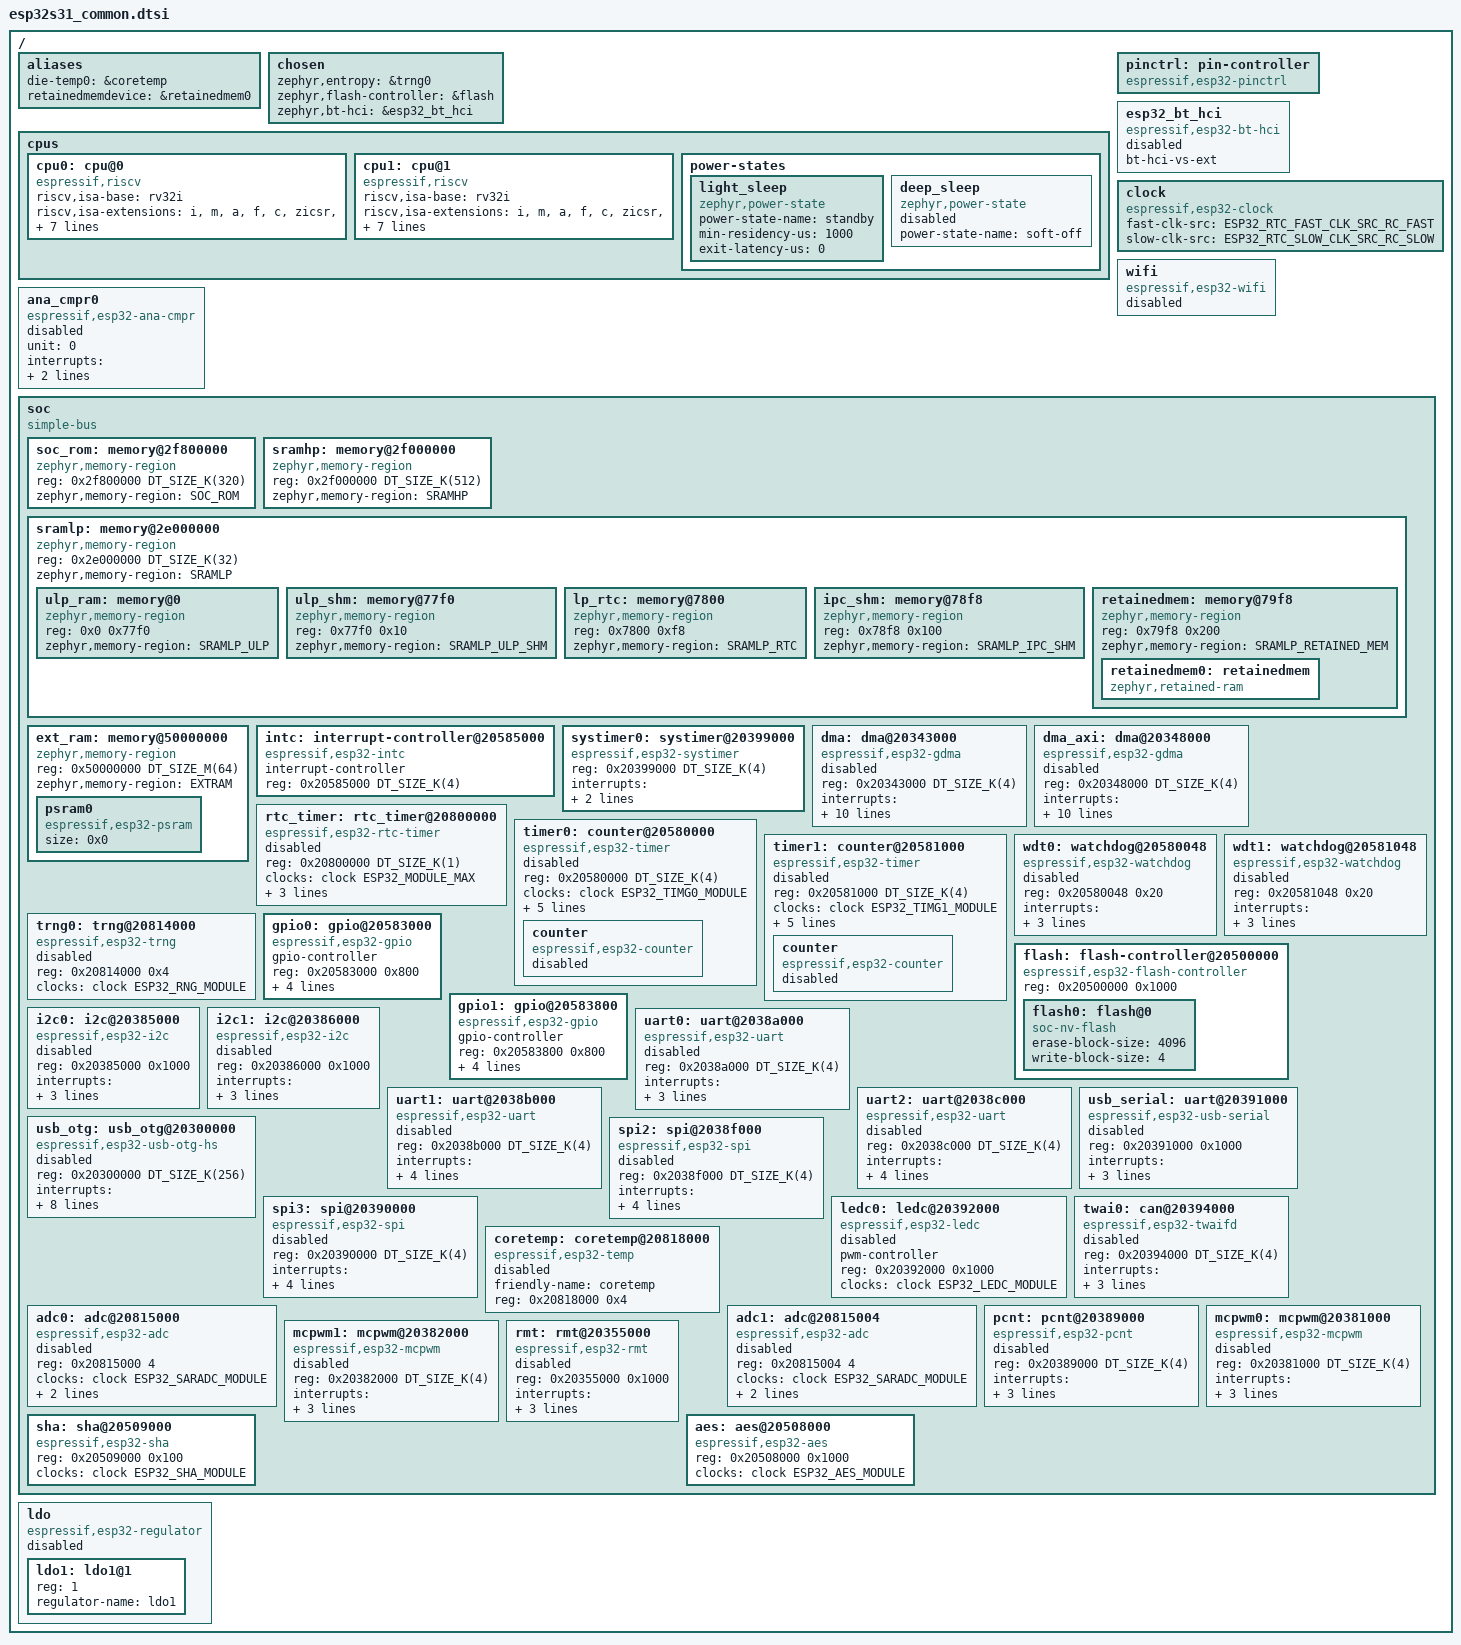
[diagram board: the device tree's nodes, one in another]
/*
 * Copyright (c) 2026 Espressif Systems (Shanghai) Co., Ltd.
 *
 * SPDX-License-Identifier: Apache-2.0
 */
#include <mem.h>
#include <freq.h>
#include <zephyr/dt-bindings/adc/adc.h>
#include <zephyr/dt-bindings/gpio/gpio.h>
#include <zephyr/dt-bindings/i2c/i2c.h>
#include <zephyr/dt-bindings/interrupt-controller/esp-esp32s31-intmux.h>
#include <zephyr/dt-bindings/clock/esp32s31_clock.h>
#include <zephyr/dt-bindings/pinctrl/esp32s31-pinctrl.h>
#include <zephyr/dt-bindings/memory-attr/memory-attr-riscv.h>

/ {
	#address-cells = <1>;
	#size-cells = <1>;

	aliases {
		die-temp0 = &coretemp;
		retainedmemdevice = &retainedmem0;
	};

	chosen {
		zephyr,entropy = &trng0;
		zephyr,flash-controller = &flash;
		zephyr,bt-hci = &esp32_bt_hci;
	};

	cpus {
		#address-cells = <1>;
		#size-cells = <0>;

		cpu0: cpu@0 {
			device_type = "cpu";
			compatible = "espressif,riscv", "riscv";
			riscv,isa-base = "rv32i";
			riscv,isa-extensions = "i", "m", "a", "f", "c", "zicsr", "zifencei";
			reg = <0>;
			cpu-power-states = <&light_sleep &deep_sleep>;
			clock-source = <ESP32_CPU_CLK_SRC_PLL>;
			clock-frequency = <DT_FREQ_M(320)>;
			xtal-freq = <DT_FREQ_M(40)>;
			d-cache-line-size = <32>;
		};

		cpu1: cpu@1 {
			device_type = "cpu";
			compatible = "espressif,riscv", "riscv";
			riscv,isa-base = "rv32i";
			riscv,isa-extensions = "i", "m", "a", "f", "c", "zicsr", "zifencei";
			reg = <1>;
			cpu-power-states = <&light_sleep &deep_sleep>;
			clock-source = <ESP32_CPU_CLK_SRC_PLL>;
			clock-frequency = <DT_FREQ_M(320)>;
			xtal-freq = <DT_FREQ_M(40)>;
			d-cache-line-size = <32>;
		};

		power-states {
			light_sleep: light_sleep {
				compatible = "zephyr,power-state";
				power-state-name = "standby";
				min-residency-us = <1000>;
				exit-latency-us = <0>;
			};

			deep_sleep: deep_sleep {
				/* Deep sleep must be entered using pm_state_force()
				 * or sys_poweroff() calls only
				 */
				compatible = "zephyr,power-state";
				power-state-name = "soft-off";
				status = "disabled";
			};
		};
	};

	pinctrl: pin-controller {
		compatible = "espressif,esp32-pinctrl";
		status = "okay";
	};

	esp32_bt_hci: esp32_bt_hci {
		compatible = "espressif,esp32-bt-hci";
		bt-hci-vs-ext;
		status = "disabled";
	};

	clock: clock {
		compatible = "espressif,esp32-clock";
		fast-clk-src = <ESP32_RTC_FAST_CLK_SRC_RC_FAST>;
		slow-clk-src = <ESP32_RTC_SLOW_CLK_SRC_RC_SLOW>;
		#clock-cells = <1>;
		status = "okay";
	};

	wifi: wifi {
		compatible = "espressif,esp32-wifi";
		status = "disabled";
	};

	ana_cmpr0: ana_cmpr0 {
		compatible = "espressif,esp32-ana-cmpr";
		unit = <0>;
		interrupts = <ZERO_DET_INTR_SOURCE IRQ_DEFAULT_PRIORITY 0>;
		interrupt-parent = <&intc>;
		status = "disabled";
	};

	soc {
		#address-cells = <1>;
		#size-cells = <1>;
		compatible = "simple-bus";
		ranges;

		/*
		 * ESP32-S31 masked ROM (0x2F800000-0x2F850000, 320 KB),
		 * containing libc and other utility functions the app calls
		 * into. PMP protection for this region is configured via
		 * PMP_SOC_REGION_DEFINE in pmp_regions.c.
		 */
		soc_rom: memory@2f800000 {
			compatible = "zephyr,memory-region";
			reg = <0x2f800000 DT_SIZE_K(320)>;
			zephyr,memory-region = "SOC_ROM";
		};

		sramhp: memory@2f000000 {
			compatible = "zephyr,memory-region", "mmio-sram";
			reg = <0x2f000000 DT_SIZE_K(512)>;
			zephyr,memory-region = "SRAMHP";
		};

		sramlp: memory@2e000000 {
			#address-cells = <1>;
			#size-cells = <1>;
			compatible = "zephyr,memory-region", "mmio-sram";
			reg = <0x2e000000 DT_SIZE_K(32)>;
			zephyr,memory-region = "SRAMLP";
			ranges = <0x0 0x2e000000 DT_SIZE_K(32)>;

			ulp_ram: memory@0 {
				compatible = "zephyr,memory-region", "mmio-sram";
				reg = <0x0 0x77f0>;
				zephyr,memory-region = "SRAMLP_ULP";
			};

			ulp_shm: memory@77f0 {
				compatible = "zephyr,memory-region", "mmio-sram";
				reg = <0x77f0 0x10>;
				zephyr,memory-region = "SRAMLP_ULP_SHM";
			};

			lp_rtc: memory@7800 {
				compatible = "zephyr,memory-region", "mmio-sram";
				reg = <0x7800 0xf8>;
				zephyr,memory-region = "SRAMLP_RTC";
			};

			ipc_shm: memory@78f8 {
				compatible = "zephyr,memory-region", "mmio-sram";
				reg = <0x78f8 0x100>;
				zephyr,memory-region = "SRAMLP_IPC_SHM";
			};

			retainedmem: memory@79f8 {
				compatible = "zephyr,memory-region", "mmio-sram";
				reg = <0x79f8 0x200>;
				ranges = <0x0 0x79f8 0x200>;
				zephyr,memory-region = "SRAMLP_RETAINED_MEM";
				status = "okay";
				#address-cells = <1>;
				#size-cells = <1>;

				retainedmem0: retainedmem {
					compatible = "zephyr,retained-ram";
					status = "okay";
					ranges;
					#address-cells = <1>;
					#size-cells = <1>;
				};
			};

			/* TODO: the LP-core mailbox (espressif,mbox-esp32) can be
			 * carved out of the remaining LP SRAM once the LP core is
			 * wired up.
			 */
		};

		ext_ram: memory@50000000 {
			compatible = "zephyr,memory-region";
			reg = <0x50000000 DT_SIZE_M(64)>;
			zephyr,memory-region = "EXTRAM";

			psram0: psram0 {
				compatible = "espressif,esp32-psram";
				size = <0x0>;
			};
		};

		intc: interrupt-controller@20585000 {
			compatible = "espressif,esp32-intc";
			#address-cells = <0>;
			#interrupt-cells = <3>;
			interrupt-controller;
			reg = <0x20585000 DT_SIZE_K(4)>;
			status = "okay";
		};

		systimer0: systimer@20399000 {
			compatible = "espressif,esp32-systimer";
			reg = <0x20399000 DT_SIZE_K(4)>;
			interrupts = <SYSTIMER_TARGET0_INTR_SOURCE IRQ_DEFAULT_PRIORITY 0>;
			interrupt-parent = <&intc>;
			status = "okay";
		};

		dma: dma@20343000 {
			compatible = "espressif,esp32-gdma";
			reg = <0x20343000 DT_SIZE_K(4)>;
			#dma-cells = <1>;
			interrupts = <AHB_PDMA_IN_CH0_INTR_SOURCE IRQ_DEFAULT_PRIORITY 0>,
				     <AHB_PDMA_OUT_CH0_INTR_SOURCE IRQ_DEFAULT_PRIORITY 0>,
				     <AHB_PDMA_IN_CH1_INTR_SOURCE IRQ_DEFAULT_PRIORITY 0>,
				     <AHB_PDMA_OUT_CH1_INTR_SOURCE IRQ_DEFAULT_PRIORITY 0>,
				     <AHB_PDMA_IN_CH2_INTR_SOURCE IRQ_DEFAULT_PRIORITY 0>,
				     <AHB_PDMA_OUT_CH2_INTR_SOURCE IRQ_DEFAULT_PRIORITY 0>;
			interrupt-parent = <&intc>;
			clocks = <&clock ESP32_GDMA_MODULE>;
			dma-channels = <6>;
			dma-buf-addr-alignment = <4>;
			status = "disabled";
		};

		dma_axi: dma@20348000 {
			compatible = "espressif,esp32-gdma";
			reg = <0x20348000 DT_SIZE_K(4)>;
			#dma-cells = <1>;
			interrupts = <AXI_PDMA_IN_CH0_INTR_SOURCE IRQ_DEFAULT_PRIORITY 0>,
				     <AXI_PDMA_OUT_CH0_INTR_SOURCE IRQ_DEFAULT_PRIORITY 0>,
				     <AXI_PDMA_IN_CH1_INTR_SOURCE IRQ_DEFAULT_PRIORITY 0>,
				     <AXI_PDMA_OUT_CH1_INTR_SOURCE IRQ_DEFAULT_PRIORITY 0>,
				     <AXI_PDMA_IN_CH2_INTR_SOURCE IRQ_DEFAULT_PRIORITY 0>,
				     <AXI_PDMA_OUT_CH2_INTR_SOURCE IRQ_DEFAULT_PRIORITY 0>;
			interrupt-parent = <&intc>;
			clocks = <&clock ESP32_GDMA_MODULE>;
			dma-channels = <6>;
			dma-buf-addr-alignment = <32>;
			status = "disabled";
		};

		rtc_timer: rtc_timer@20800000 {
			compatible = "espressif,esp32-rtc-timer";
			reg = <0x20800000 DT_SIZE_K(1)>;
			clocks = <&clock ESP32_MODULE_MAX>;
			interrupts = <LP_TIMER_REG_0_INTR_SOURCE IRQ_DEFAULT_PRIORITY 0>;
			interrupt-parent = <&intc>;
			status = "disabled";
		};

		timer0: counter@20580000 {
			compatible = "espressif,esp32-timer";
			reg = <0x20580000 DT_SIZE_K(4)>;
			clocks = <&clock ESP32_TIMG0_MODULE>;
			group = <0>;
			index = <0>;
			interrupts = <TIMERGRP0_T0_INTR_SOURCE IRQ_DEFAULT_PRIORITY 0>;
			interrupt-parent = <&intc>;
			status = "disabled";

			counter {
				compatible = "espressif,esp32-counter";
				status = "disabled";
			};
		};

		timer1: counter@20581000 {
			compatible = "espressif,esp32-timer";
			reg = <0x20581000 DT_SIZE_K(4)>;
			clocks = <&clock ESP32_TIMG1_MODULE>;
			group = <1>;
			index = <0>;
			interrupts = <TIMERGRP1_T0_INTR_SOURCE IRQ_DEFAULT_PRIORITY 0>;
			interrupt-parent = <&intc>;
			status = "disabled";

			counter {
				compatible = "espressif,esp32-counter";
				status = "disabled";
			};
		};

		wdt0: watchdog@20580048 {
			compatible = "espressif,esp32-watchdog";
			reg = <0x20580048 0x20>;
			interrupts = <TIMERGRP0_WDT_INTR_SOURCE IRQ_DEFAULT_PRIORITY 0>;
			interrupt-parent = <&intc>;
			clocks = <&clock ESP32_TIMG0_MODULE>;
			status = "disabled";
		};

		wdt1: watchdog@20581048 {
			compatible = "espressif,esp32-watchdog";
			reg = <0x20581048 0x20>;
			interrupts = <TIMERGRP1_WDT_INTR_SOURCE IRQ_DEFAULT_PRIORITY 0>;
			interrupt-parent = <&intc>;
			clocks = <&clock ESP32_TIMG1_MODULE>;
			status = "disabled";
		};

		trng0: trng@20814000 {
			compatible = "espressif,esp32-trng";
			reg = <0x20814000 0x4>;
			clocks = <&clock ESP32_RNG_MODULE>;
			status = "disabled";
		};

		flash: flash-controller@20500000 {
			compatible = "espressif,esp32-flash-controller";
			reg = <0x20500000 0x1000>;

			#address-cells = <1>;
			#size-cells = <1>;
			ranges;

			flash0: flash@0 {
				compatible = "soc-nv-flash";
				erase-block-size = <4096>;
				write-block-size = <4>;
				#address-cells = <1>;
				#size-cells = <1>;
				/* reg and ranges are specified in SOC/SIP dtsi */
			};
		};

		gpio0: gpio@20583000 {
			compatible = "espressif,esp32-gpio";
			gpio-controller;
			#gpio-cells = <2>;
			reg = <0x20583000 0x800>;
			interrupts = <GPIO_INTR0_SOURCE IRQ_DEFAULT_PRIORITY 0>;
			interrupt-parent = <&intc>;
			ngpios = <32>;
		};

		gpio1: gpio@20583800 {
			compatible = "espressif,esp32-gpio";
			gpio-controller;
			#gpio-cells = <2>;
			reg = <0x20583800 0x800>;
			interrupts = <GPIO_INTR0_SOURCE IRQ_DEFAULT_PRIORITY 0>;
			interrupt-parent = <&intc>;
			ngpios = <30>;
		};

		i2c0: i2c@20385000 {
			compatible = "espressif,esp32-i2c";
			#address-cells = <1>;
			#size-cells = <0>;
			reg = <0x20385000 0x1000>;
			interrupts = <I2C0_INTR_SOURCE IRQ_DEFAULT_PRIORITY 0>;
			interrupt-parent = <&intc>;
			clocks = <&clock ESP32_I2C0_MODULE>;
			status = "disabled";
		};

		i2c1: i2c@20386000 {
			compatible = "espressif,esp32-i2c";
			#address-cells = <1>;
			#size-cells = <0>;
			reg = <0x20386000 0x1000>;
			interrupts = <I2C1_INTR_SOURCE IRQ_DEFAULT_PRIORITY 0>;
			interrupt-parent = <&intc>;
			clocks = <&clock ESP32_I2C1_MODULE>;
			status = "disabled";
		};

		uart0: uart@2038a000 {
			compatible = "espressif,esp32-uart";
			reg = <0x2038a000 DT_SIZE_K(4)>;
			status = "disabled";
			interrupts = <UART0_INTR_SOURCE IRQ_DEFAULT_PRIORITY 0>;
			interrupt-parent = <&intc>;
			clocks = <&clock ESP32_UART0_MODULE>;
		};

		uart1: uart@2038b000 {
			compatible = "espressif,esp32-uart";
			reg = <0x2038b000 DT_SIZE_K(4)>;
			status = "disabled";
			interrupts = <UART1_INTR_SOURCE IRQ_DEFAULT_PRIORITY 0>;
			interrupt-parent = <&intc>;
			clocks = <&clock ESP32_UART1_MODULE>;
			current-speed = <115200>;
		};

		uart2: uart@2038c000 {
			compatible = "espressif,esp32-uart";
			reg = <0x2038c000 DT_SIZE_K(4)>;
			status = "disabled";
			interrupts = <UART2_INTR_SOURCE IRQ_DEFAULT_PRIORITY 0>;
			interrupt-parent = <&intc>;
			clocks = <&clock ESP32_UART2_MODULE>;
			current-speed = <115200>;
		};

		usb_serial: uart@20391000 {
			compatible = "espressif,esp32-usb-serial";
			reg = <0x20391000 0x1000>;
			status = "disabled";
			interrupts = <USB_SERIAL_JTAG_INTR_SOURCE IRQ_DEFAULT_PRIORITY 0>;
			interrupt-parent = <&intc>;
			clocks = <&clock ESP32_USB_MODULE>;
		};

		usb_otg: usb_otg@20300000 {
			compatible = "espressif,esp32-usb-otg-hs", "snps,dwc2";
			reg = <0x20300000 DT_SIZE_K(256)>;
			status = "disabled";
			interrupts = <USB_OTGHS_INTR_SOURCE IRQ_DEFAULT_PRIORITY 0>;
			interrupt-parent = <&intc>;
			clocks = <&clock ESP32_USB_OTG_MODULE>;
			num-out-eps = <8>;
			num-in-eps = <8>;
			ghwcfg1 = <0x00000000>;
			ghwcfg2 = <0x239ffed2>;
			ghwcfg4 = <0xde11aa30>;
		};

		spi2: spi@2038f000 {
			compatible = "espressif,esp32-spi";
			reg = <0x2038f000 DT_SIZE_K(4)>;
			interrupts = <SPI2_INTR_SOURCE IRQ_DEFAULT_PRIORITY 0>;
			interrupt-parent = <&intc>;
			clocks = <&clock ESP32_SPI2_MODULE>;
			dma-host = <0>;
			status = "disabled";
		};

		spi3: spi@20390000 {
			compatible = "espressif,esp32-spi";
			reg = <0x20390000 DT_SIZE_K(4)>;
			interrupts = <SPI3_INTR_SOURCE IRQ_DEFAULT_PRIORITY 0>;
			interrupt-parent = <&intc>;
			clocks = <&clock ESP32_SPI3_MODULE>;
			dma-host = <1>;
			status = "disabled";
		};

		ledc0: ledc@20392000 {
			compatible = "espressif,esp32-ledc";
			pwm-controller;
			#pwm-cells = <3>;
			reg = <0x20392000 0x1000>;
			clocks = <&clock ESP32_LEDC_MODULE>;
			status = "disabled";
		};

		twai0: can@20394000 {
			compatible = "espressif,esp32-twaifd";
			reg = <0x20394000 DT_SIZE_K(4)>;
			interrupts = <TWAI0_INTR_SOURCE IRQ_DEFAULT_PRIORITY 0>;
			interrupt-parent = <&intc>;
			clocks = <&clock ESP32_TWAI0_MODULE>;
			status = "disabled";
		};

		coretemp: coretemp@20818000 {
			compatible = "espressif,esp32-temp";
			friendly-name = "coretemp";
			reg = <0x20818000 0x4>;
			status = "disabled";
		};

		adc0: adc@20815000 {
			compatible = "espressif,esp32-adc";
			reg = <0x20815000 4>;
			clocks = <&clock ESP32_SARADC_MODULE>;
			unit = <1>;
			channel-count = <8>;
			#io-channel-cells = <1>;
			status = "disabled";
		};

		adc1: adc@20815004 {
			compatible = "espressif,esp32-adc";
			reg = <0x20815004 4>;
			clocks = <&clock ESP32_SARADC_MODULE>;
			unit = <2>;
			channel-count = <8>;
			#io-channel-cells = <1>;
			status = "disabled";
		};

		pcnt: pcnt@20389000 {
			compatible = "espressif,esp32-pcnt";
			reg = <0x20389000 DT_SIZE_K(4)>;
			interrupts = <PCNT0_INTR_SOURCE IRQ_DEFAULT_PRIORITY 0>;
			interrupt-parent = <&intc>;
			clocks = <&clock ESP32_PCNT_MODULE>;
			status = "disabled";
		};

		mcpwm0: mcpwm@20381000 {
			compatible = "espressif,esp32-mcpwm";
			reg = <0x20381000 DT_SIZE_K(4)>;
			interrupts = <PWM0_INTR_SOURCE IRQ_DEFAULT_PRIORITY 0>;
			interrupt-parent = <&intc>;
			clocks = <&clock ESP32_MCPWM0_MODULE>;
			#pwm-cells = <3>;
			status = "disabled";
		};

		mcpwm1: mcpwm@20382000 {
			compatible = "espressif,esp32-mcpwm";
			reg = <0x20382000 DT_SIZE_K(4)>;
			interrupts = <PWM1_INTR_SOURCE IRQ_DEFAULT_PRIORITY 0>;
			interrupt-parent = <&intc>;
			clocks = <&clock ESP32_MCPWM1_MODULE>;
			#pwm-cells = <3>;
			status = "disabled";
		};

		rmt: rmt@20355000 {
			compatible = "espressif,esp32-rmt";
			#pulse-io-cells = <1>;
			reg = <0x20355000 0x1000>;
			interrupts = <RMT_INTR_SOURCE IRQ_DEFAULT_PRIORITY 0>;
			interrupt-parent = <&intc>;
			clocks = <&clock ESP32_RMT_MODULE>;
			status = "disabled";
		};

		sha: sha@20509000 {
			compatible = "espressif,esp32-sha";
			reg = <0x20509000 0x100>;
			clocks = <&clock ESP32_SHA_MODULE>;
			status = "okay";
		};

		aes: aes@20508000 {
			compatible = "espressif,esp32-aes";
			reg = <0x20508000 0x1000>;
			clocks = <&clock ESP32_AES_MODULE>;
			status = "okay";
		};
	};

	/*
	 * ESP32-S31 has a single general-purpose internal LDO channel. By
	 * default it is reserved to power the external PSRAM (and MPLL). A
	 * board that powers PSRAM externally can repurpose or disable it.
	 */
	ldo: ldo {
		compatible = "espressif,esp32-regulator";
		#address-cells = <1>;
		#size-cells = <0>;
		status = "disabled";

		ldo1: ldo1@1 {
			reg = <1>;
			regulator-name = "ldo1";
		};
	};
};
